# ESP32-P4 register map
Vendor: ESPRESSIF SYSTEMS (SHANGHAI) CO., LTD.; File version: 2
ESP32-P4 EMAC (extracted from the TRM)
Registers are 32-bit, read-write, reset 0x0 unless marked. A register's access mark holds for its fields unless they carry their own. Offsets are from the block's base; lines under a group give offsets from that group; [hi:lo] are bit positions; {n}, {i} and the like mark numbered series; 'fields as' and 'values as' point back to an identical list; <NAME> marks a mode.

## Memory map
0x50098000 EMAC — Ethernet MAC (DesignWare 10/100 MAC + DMA)

## EMAC — Ethernet MAC (DesignWare 10/100 MAC + DMA)
Base 0x50098000
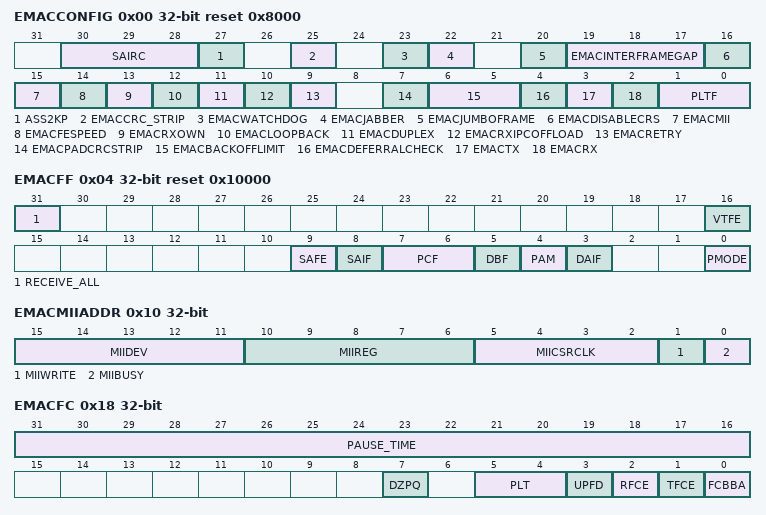
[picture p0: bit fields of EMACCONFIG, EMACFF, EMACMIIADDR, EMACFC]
0x00 EMACCONFIG reset 0x8000
  [30:28] SAIRC, [27] ASS2KP, [25] EMACCRC_STRIP, [23] EMACWATCHDOG, [22] EMACJABBER, [20] EMACJUMBOFRAME, [19:17] EMACINTERFRAMEGAP, [16] EMACDISABLECRS, [15] EMACMII, [14] EMACFESPEED, [13] EMACRXOWN, [12] EMACLOOPBACK, [11] EMACDUPLEX, [10] EMACRXIPCOFFLOAD, [9] EMACRETRY, [7] EMACPADCRCSTRIP, [6:5] EMACBACKOFFLIMIT, [4] EMACDEFERRALCHECK, [3] EMACTX, [2] EMACRX, [1:0] PLTF
0x04 EMACFF reset 0x10000
  [31] RECEIVE_ALL, [16] VTFE, [9] SAFE, [8] SAIF, [7:6] PCF, [5] DBF, [4] PAM, [3] DAIF, [0] PMODE
0x10 EMACMIIADDR
  [15:11] MIIDEV, [10:6] MIIREG, [5:2] MIICSRCLK, [1] MIIWRITE, [0] MIIBUSY
0x14 EMACMIIDATA
  [15:0] MII_DATA
0x18 EMACFC
  [31:16] PAUSE_TIME, [7] DZPQ, [5:4] PLT, [3] UPFD, [2] RFCE, [1] TFCE, [0] FCBBA
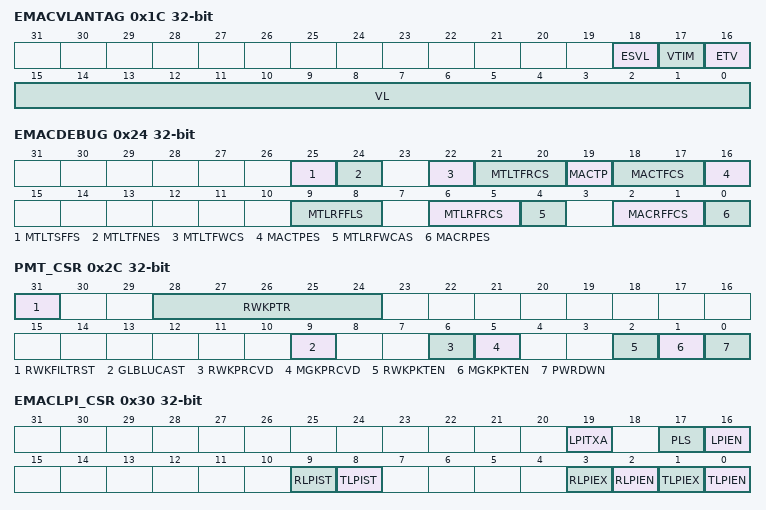
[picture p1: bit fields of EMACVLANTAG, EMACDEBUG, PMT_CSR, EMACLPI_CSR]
0x1C EMACVLANTAG
  [18] ESVL, [17] VTIM, [16] ETV, [15:0] VL
0x24 EMACDEBUG
  [25] MTLTSFFS, [24] MTLTFNES, [22] MTLTFWCS, [21:20] MTLTFRCS, [19] MACTP, [18:17] MACTFCS, [16] MACTPES, [9:8] MTLRFFLS, [6:5] MTLRFRCS, [4] MTLRFWCAS, [2:1] MACRFFCS, [0] MACRPES
0x28 PMT_RWUFFR
0x2C PMT_CSR
  [31] RWKFILTRST, [28:24] RWKPTR, [9] GLBLUCAST, [6] RWKPRCVD, [5] MGKPRCVD, [2] RWKPKTEN, [1] MGKPKTEN, [0] PWRDWN
0x30 EMACLPI_CSR
  [19] LPITXA, [17] PLS, [16] LPIEN, [9] RLPIST, [8] TLPIST, [3] RLPIEX, [2] RLPIEN, [1] TLPIEX, [0] TLPIEN
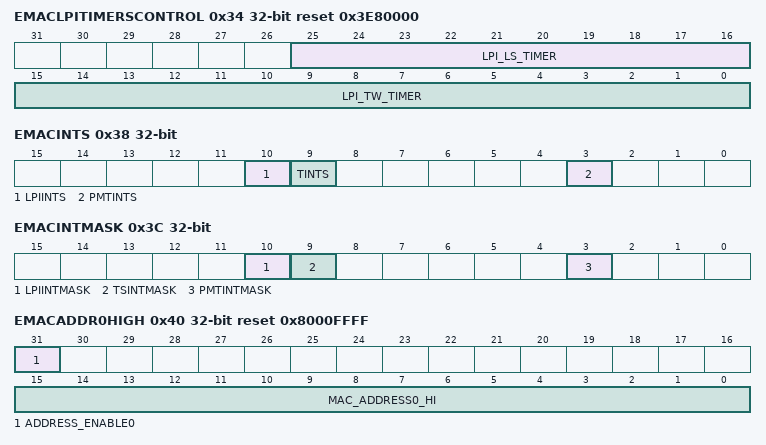
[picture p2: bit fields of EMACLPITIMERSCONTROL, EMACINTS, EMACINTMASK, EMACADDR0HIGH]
0x34 EMACLPITIMERSCONTROL reset 0x3E80000
  [25:16] LPI_LS_TIMER, [15:0] LPI_TW_TIMER
0x38 EMACINTS
  [10] LPIINTS, [9] TINTS, [3] PMTINTS
0x3C EMACINTMASK
  [10] LPIINTMASK, [9] TSINTMASK, [3] PMTINTMASK
0x40 EMACADDR0HIGH reset 0x8000FFFF
  [31] ADDRESS_ENABLE0, [15:0] MAC_ADDRESS0_HI
{0x44+8i} EMACADDR{i}LOW reset 0xFFFFFFFF (i=0..8)
  [31:0] ADDRESS_LOW
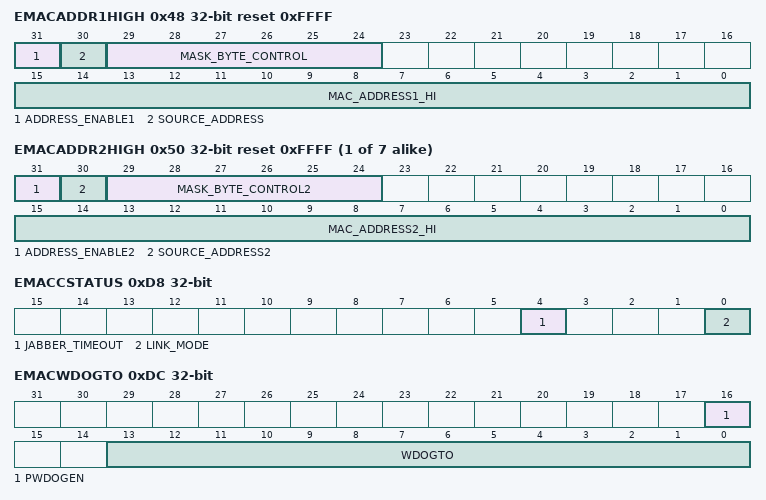
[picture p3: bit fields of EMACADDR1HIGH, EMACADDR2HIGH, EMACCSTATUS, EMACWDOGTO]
0x48 EMACADDR1HIGH reset 0xFFFF
  [31] ADDRESS_ENABLE1, [30] SOURCE_ADDRESS, [29:24] MASK_BYTE_CONTROL, [15:0] MAC_ADDRESS1_HI
{0x40+8i} EMACADDR{i}HIGH reset 0xFFFF (i=2..8)
  [31] ADDRESS_ENABLE{i}, [30] SOURCE_ADDRESS{i}, [29:24] MASK_BYTE_CONTROL{i}, [15:0] MAC_ADDRESS{i}_HI
0xD8 EMACCSTATUS
  [4] JABBER_TIMEOUT, [0] LINK_MODE
0xDC EMACWDOGTO
  [16] PWDOGEN, [13:0] WDOGTO
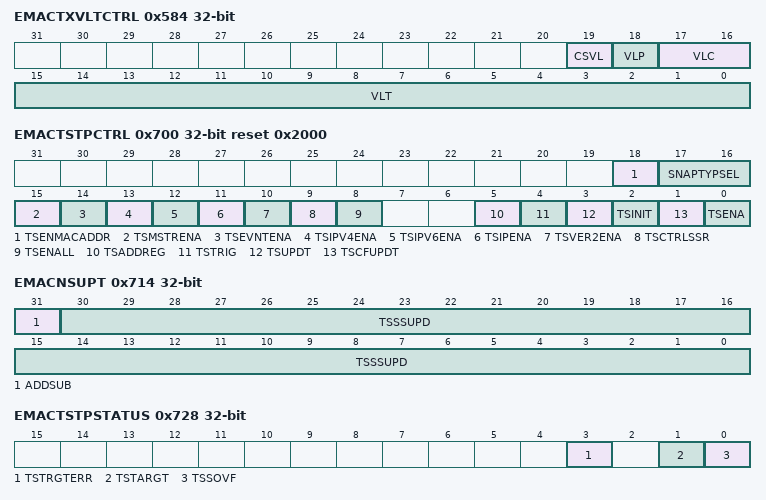
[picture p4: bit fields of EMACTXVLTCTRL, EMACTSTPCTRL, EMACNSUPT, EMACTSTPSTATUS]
0x584 EMACTXVLTCTRL
  [19] CSVL, [18] VLP, [17:16] VLC, [15:0] VLT
0x700 EMACTSTPCTRL reset 0x2000
  [18] TSENMACADDR, [17:16] SNAPTYPSEL, [15] TSMSTRENA, [14] TSEVNTENA, [13] TSIPV4ENA, [12] TSIPV6ENA, [11] TSIPENA, [10] TSVER2ENA, [9] TSCTRLSSR, [8] TSENALL, [5] TSADDREG, [4] TSTRIG, [3] TSUPDT, [2] TSINIT, [1] TSCFUPDT, [0] TSENA
0x704 EMACSUB2NDINCR
  [7:0] SSINC
0x708 EMACSYSTIM2ND
  [31:0] ADDRESS_LOW
0x70C EMACSYSTIMNS
  [30:0] TSSS
0x710 EMAC2NDUPT
  [31:0] ADDRESS_LOW
0x714 EMACNSUPT
  [31] ADDSUB, [30:0] TSSSUPD
0x718 EMACTSTPADDEND
  [31:0] ADDRESS_LOW
0x71C EMACTGTIME2ND
  [31:0] ADDRESS_LOW
0x720 EMACTGTIMENS
  [30:0] TTSLO
0x724 EMACSYSTIMHIGHWORD2ND
  [15:0] TSHWR
0x728 EMACTSTPSTATUS
  [3] TSTRGTERR, [1] TSTARGT, [0] TSSOVF
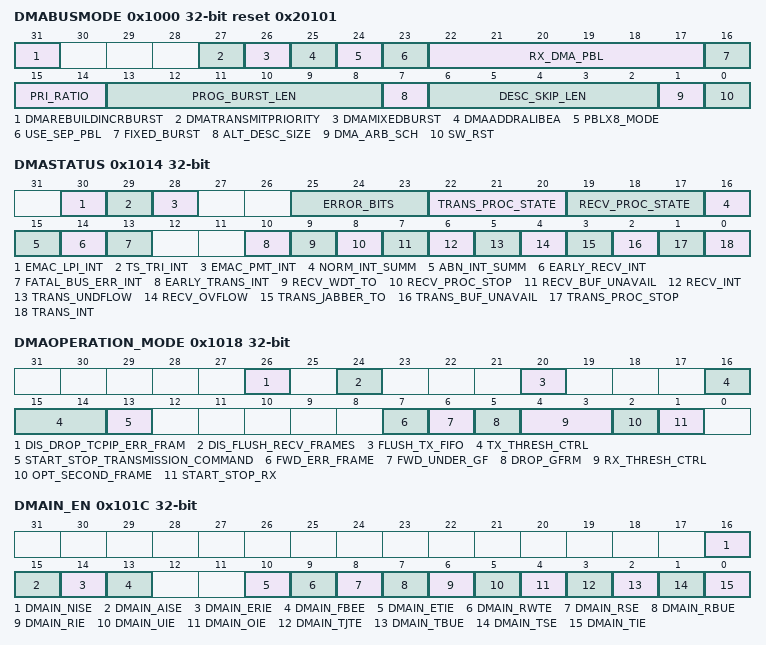
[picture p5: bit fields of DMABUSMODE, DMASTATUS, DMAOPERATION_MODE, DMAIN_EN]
0x1000 DMABUSMODE reset 0x20101
  [31] DMAREBUILDINCRBURST, [27] DMATRANSMITPRIORITY, [26] DMAMIXEDBURST, [25] DMAADDRALIBEA, [24] PBLX8_MODE, [23] USE_SEP_PBL, [22:17] RX_DMA_PBL, [16] FIXED_BURST, [15:14] PRI_RATIO, [13:8] PROG_BURST_LEN, [7] ALT_DESC_SIZE, [6:2] DESC_SKIP_LEN, [1] DMA_ARB_SCH, [0] SW_RST
0x1004 DMATXPOLLDEMAND
  [31:0] TRANS_POLL_DEMAND
0x1008 DMARXPOLLDEMAND
  [31:0] RECV_POLL_DEMAND
0x100C DMARXBASEADDR
  [31:0] START_RECV_LIST
0x1010 DMATXBASEADDR
  [31:0] START_TRANS_LIST
0x1014 DMASTATUS
  [30] EMAC_LPI_INT, [29] TS_TRI_INT, [28] EMAC_PMT_INT, [25:23] ERROR_BITS, [22:20] TRANS_PROC_STATE, [19:17] RECV_PROC_STATE, [16] NORM_INT_SUMM, [15] ABN_INT_SUMM, [14] EARLY_RECV_INT, [13] FATAL_BUS_ERR_INT, [10] EARLY_TRANS_INT, [9] RECV_WDT_TO, [8] RECV_PROC_STOP, [7] RECV_BUF_UNAVAIL, [6] RECV_INT, [5] TRANS_UNDFLOW, [4] RECV_OVFLOW, [3] TRANS_JABBER_TO, [2] TRANS_BUF_UNAVAIL, [1] TRANS_PROC_STOP, [0] TRANS_INT
0x1018 DMAOPERATION_MODE
  [26] DIS_DROP_TCPIP_ERR_FRAM, [24] DIS_FLUSH_RECV_FRAMES, [20] FLUSH_TX_FIFO, [16:14] TX_THRESH_CTRL, [13] START_STOP_TRANSMISSION_COMMAND, [7] FWD_ERR_FRAME, [6] FWD_UNDER_GF, [5] DROP_GFRM, [4:3] RX_THRESH_CTRL, [2] OPT_SECOND_FRAME, [1] START_STOP_RX
0x101C DMAIN_EN
  [16] DMAIN_NISE, [15] DMAIN_AISE, [14] DMAIN_ERIE, [13] DMAIN_FBEE, [10] DMAIN_ETIE, [9] DMAIN_RWTE, [8] DMAIN_RSE, [7] DMAIN_RBUE, [6] DMAIN_RIE, [5] DMAIN_UIE, [4] DMAIN_OIE, [3] DMAIN_TJTE, [2] DMAIN_TBUE, [1] DMAIN_TSE, [0] DMAIN_TIE
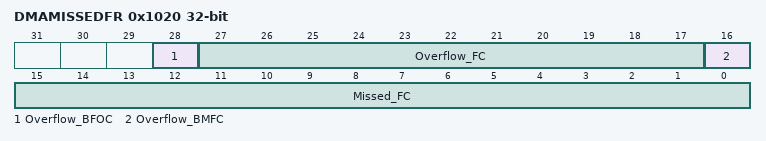
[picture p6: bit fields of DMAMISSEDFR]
0x1020 DMAMISSEDFR
  [28] Overflow_BFOC, [27:17] Overflow_FC, [16] Overflow_BMFC, [15:0] Missed_FC
0x1024 DMARINTWDTIMER
  [7:0] RIWTC
0x102C DMAAHBSTATUS
  [0] AHB_ST
0x1048 DMATXCURRDESC
  [31:0] ADDRESS_LOW
0x104C DMARXCURRDESC
  [31:0] ADDRESS_LOW
0x1050 DMATXCURRADDR_BUF
  [31:0] ADDRESS_LOW
0x1054 DMARXCURRADDR_BUF
  [31:0] ADDRESS_LOW
